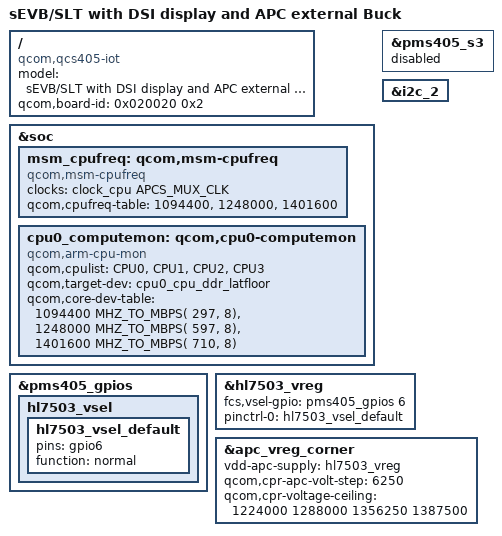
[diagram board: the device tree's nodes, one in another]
/*
 * Copyright (c) 2018-2019, The Linux Foundation. All rights reserved.
 *
 * This program is free software; you can redistribute it and/or modify
 * it under the terms of the GNU General Public License version 2 and
 * only version 2 as published by the Free Software Foundation.
 *
 * This program is distributed in the hope that it will be useful,
 * but WITHOUT ANY WARRANTY; without even the implied warranty of
 * MERCHANTABILITY or FITNESS FOR A PARTICULAR PURPOSE.  See the
 * GNU General Public License for more details.
 */

/dts-v1/;

#include "qcs405.dtsi"

/ {
	model = "sEVB/SLT with DSI display and APC external Buck";
	compatible = "qcom,qcs405-iot", "qcom,qcs405", "qcom,iot";
	qcom,board-id = <0x020020 0x2>;
};

&soc {
	/delete-node/ qcom,msm-cpufreq;

	msm_cpufreq: qcom,msm-cpufreq {
		compatible = "qcom,msm-cpufreq";
		clock-names = "cpu0_clk";
		clocks = <&clock_cpu APCS_MUX_CLK>;

		qcom,cpufreq-table =
			< 1094400 >,
			< 1248000 >,
			< 1401600 >;
	};

	/delete-node/ qcom,cpu0-computemon;

	cpu0_computemon: qcom,cpu0-computemon {
		compatible = "qcom,arm-cpu-mon";
		qcom,cpulist = <&CPU0 &CPU1 &CPU2 &CPU3>;
		qcom,target-dev = <&cpu0_cpu_ddr_latfloor>;
		qcom,core-dev-table =
			< 1094400 MHZ_TO_MBPS( 297, 8) >,
			< 1248000 MHZ_TO_MBPS( 597, 8) >,
			< 1401600 MHZ_TO_MBPS( 710, 8) >;
	};
};

&pms405_s3 {
	status = "disabled";
};

&pms405_gpios {
	hl7503_vsel {
		hl7503_vsel_default: hl7503_vsel_default {
			pins = "gpio6";
			function = "normal";
		};
	};
};

&i2c_2 {
	status = "ok";
};

&hl7503_vreg {
	status = "ok";
	fcs,vsel-gpio = <&pms405_gpios 6 GPIO_ACTIVE_HIGH>;
	pinctrl-names = "default";
	pinctrl-0 = <&hl7503_vsel_default>;
};

&apc_vreg_corner {
	vdd-apc-supply = <&hl7503_vreg>;
	qcom,cpr-apc-volt-step = <6250>;
	qcom,cpr-voltage-ceiling = <1224000 1288000 1356250 1387500>;
};
